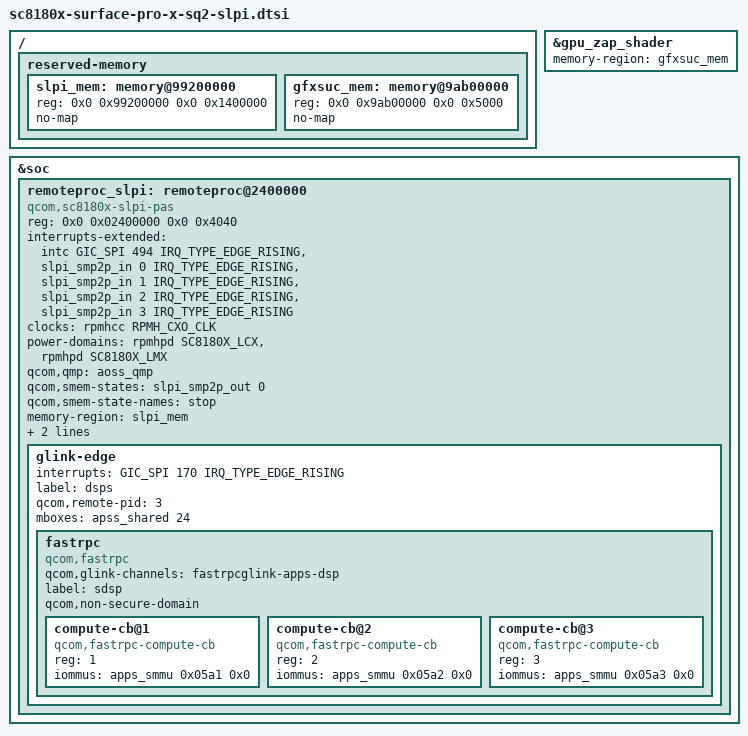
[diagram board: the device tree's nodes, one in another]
// SPDX-License-Identifier: GPL-2.0-only
/*
 * Qualcomm SC8180X SLPI (Sensors Low-Power Island) & FastRPC enablement
 * for Microsoft Surface Pro X (SQ2).
 *
 * Exposes the LSM6DSO 6-axis IMU and AK0991x magnetometer/compass through
 * FastRPC (/dev/fastrpc-sdsp) + hexagonrpcd + QMI SSC (libssc / iio-sensor-proxy).
 *
 * Using compatible "qcom,sc8180x-slpi-pas", "qcom,sm8150-slpi-pas" allows
 * probing on stock Linux 7.3 qcom_q6v5_pas (which maps sm8150-slpi-pas to
 * sdm845_slpi_resource_init, PAS ID 12) as well as newer kernels with an
 * explicit sc8180x-slpi-pas match entry.
 */

#include <dt-bindings/interrupt-controller/arm-gic.h>
#include <dt-bindings/power/qcom,rpmhpd.h>

/ {
	reserved-memory {
		/* Expand SLPI reservation to full 20 MiB required by qcslpi8180.mbn */
		slpi_mem: memory@99200000 {
			reg = <0x0 0x99200000 0x0 0x1400000>;
			no-map;
		};

		/* Relocate relocatable GPU zap-shader above SLPI/Venus window */
		gfxsuc_mem: memory@9ab00000 {
			reg = <0x0 0x9ab00000 0x0 0x5000>;
			no-map;
		};
	};
};

&gpu_zap_shader {
	memory-region = <&gfxsuc_mem>;
};

&soc {
	remoteproc_slpi: remoteproc@2400000 {
		compatible = "qcom,sc8180x-slpi-pas", "qcom,sm8150-slpi-pas";
		reg = <0x0 0x02400000 0x0 0x4040>;

		interrupts-extended = <&intc GIC_SPI 494 IRQ_TYPE_EDGE_RISING>,
				      <&slpi_smp2p_in 0 IRQ_TYPE_EDGE_RISING>,
				      <&slpi_smp2p_in 1 IRQ_TYPE_EDGE_RISING>,
				      <&slpi_smp2p_in 2 IRQ_TYPE_EDGE_RISING>,
				      <&slpi_smp2p_in 3 IRQ_TYPE_EDGE_RISING>;
		interrupt-names = "wdog", "fatal", "ready", "handover", "stop-ack";

		clocks = <&rpmhcc RPMH_CXO_CLK>;
		clock-names = "xo";

		power-domains = <&rpmhpd SC8180X_LCX>,
				<&rpmhpd SC8180X_LMX>;
		power-domain-names = "lcx", "lmx";

		qcom,qmp = <&aoss_qmp>;

		qcom,smem-states = <&slpi_smp2p_out 0>;
		qcom,smem-state-names = "stop";

		memory-region = <&slpi_mem>;
		firmware-name = "qcom/msft/surface/pro-x-sq2/qcslpi8180.mbn";
		status = "okay";

		glink-edge {
			interrupts = <GIC_SPI 170 IRQ_TYPE_EDGE_RISING>;
			label = "dsps";
			qcom,remote-pid = <3>;
			mboxes = <&apss_shared 24>;

			fastrpc {
				compatible = "qcom,fastrpc";
				qcom,glink-channels = "fastrpcglink-apps-dsp";
				label = "sdsp";
				qcom,non-secure-domain;
				#address-cells = <1>;
				#size-cells = <0>;

				compute-cb@1 {
					compatible = "qcom,fastrpc-compute-cb";
					reg = <1>;
					iommus = <&apps_smmu 0x05a1 0x0>;
				};

				compute-cb@2 {
					compatible = "qcom,fastrpc-compute-cb";
					reg = <2>;
					iommus = <&apps_smmu 0x05a2 0x0>;
				};

				compute-cb@3 {
					compatible = "qcom,fastrpc-compute-cb";
					reg = <3>;
					iommus = <&apps_smmu 0x05a3 0x0>;
				};
			};
		};
	};
};
